# GD32VW553x register map
File version: 1.0
CPU: other RISC-V, little endian, no MPU, FPU
Registers are 32-bit, read-write, reset 0x0 unless marked. A register's access mark holds for its fields unless they carry their own. Offsets are from the block's base; [hi:lo] are bit positions; {n}, {i} and the like mark numbered series.

## SPI — Serial peripheral interface
Base 0x40013000
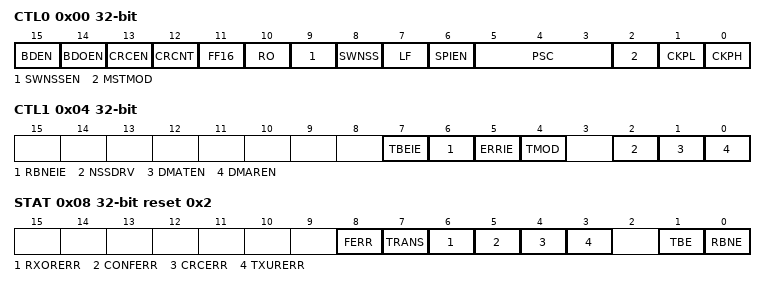
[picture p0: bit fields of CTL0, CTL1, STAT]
0x00 CTL0 — Control register 0
  [15] BDEN — Bidirectional enable
  [14] BDOEN — Bidirectional transmit output enable
  [13] CRCEN — CRC calculation enable
  [12] CRCNT — CRC next transfer
  [11] FF16 — Data frame format
  [10] RO — Receive only mode
  [9] SWNSSEN — NSS software mode enable
  [8] SWNSS — NSS pin selection in NSS software mode
  [7] LF — LSB first mode
  [6] SPIEN — SPI enable
  [5:3] PSC — Master clock prescaler selection
  [2] MSTMOD — Master mode enable
  [1] CKPL — Clock polarity selection
  [0] CKPH — Clock phase selection
0x04 CTL1 — Control register 1
  [7] TBEIE — Transmit buffer empty interrupt enable
  [6] RBNEIE — Receive buffer not empty interrupt enable
  [5] ERRIE — Errors interrupt enable
  [4] TMOD — SPI TI mode enable
  [2] NSSDRV — Drive NSS output
  [1] DMATEN — Transmit buffer DMA enable
  [0] DMAREN — Receive buffer DMA enable
0x08 STAT access per field reset 0x2 — Status register
  [8] FERR rw — Format error
  [7] TRANS ro — Transmitting ongoing bit
  [6] RXORERR ro — Reception overrun error bit
  [5] CONFERR ro — SPI Configuration error
  [4] CRCERR rw — SPI CRC error bit
  [3] TXURERR ro — Transmission underrun error bit
  [1] TBE ro — Transmit buffer empty
  [0] RBNE ro — Receive buffer not empty
0x0C DATA
  [15:0] SPI_DATA — Data transfer register
0x10 CRCPOLY reset 0x7 — CRC polynomial register
  [15:0] CRCPOLY — CRC polynomial value
0x14 RCRC ro — RX CRC register
  [15:0] RCRC — RX CRC value
0x18 TCRC ro — TX CRC register
  [15:0] TCRC — TX CRC value

## SYSCFG — System configuration registers
Base 0x40013800
0x00 CFG0 ro — Configuration register 0
  [1:0] BOOT_MODE — Boot mode (Refer to Boot configuration for details)
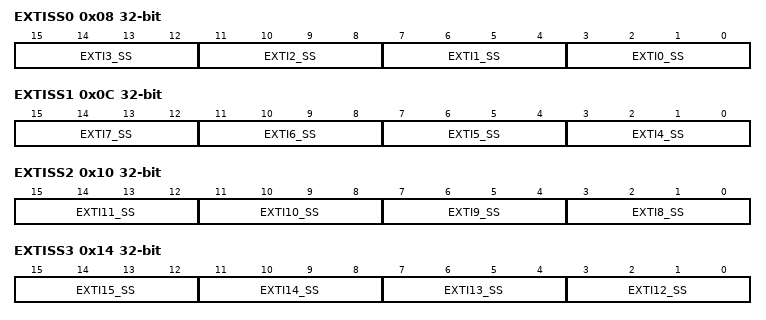
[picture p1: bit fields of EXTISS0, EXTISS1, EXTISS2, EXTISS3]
0x08 EXTISS0 — EXTI sources selection register 0
  [4n+3:4n] EXTI{n}_SS (n=0..3) — EXTI {n} sources selection
0x0C EXTISS1 — EXTI sources selection register 1
  [4n-13:4n-16] EXTI{n}_SS (n=4..7) — EXTI {n} sources selection
0x10 EXTISS2 — EXTI sources selection register 2
  [4n-29:4n-32] EXTI{n}_SS (n=8..11) — EXTI {n} sources selection
0x14 EXTISS3 — EXTI sources selection register 3
  [4n-45:4n-48] EXTI{n}_SS (n=12..15) — EXTI {n} sources selection
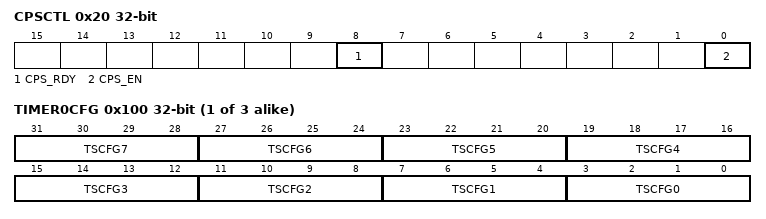
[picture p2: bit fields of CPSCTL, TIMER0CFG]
0x20 CPSCTL access per field — I/O compensation control register
  [8] CPS_RDY ro — Compensation cell ready flag
  [0] CPS_EN rw — Compensation cell power-down
0x54 CFG1 ro — SYSCFG configuration register 1
  [2] LVD_LOCK — LVD lockup bit
0x68 SCFG reset 0x1 — SYSCFG shared SRAM configuration register
  [0] SOWNSEL — Shared SRAM ownership select
{0x100+4i} TIMER{i}CFG (i=0..2) — TIMER trigger selection regist {i}
  [4n+3:4n] TSCFG{n} (n=0..7) — Trigger selection {n}

## TIMER15 — General-purpose-timers
Base 0x40018000
Same registers: TIMER16 0x40018400
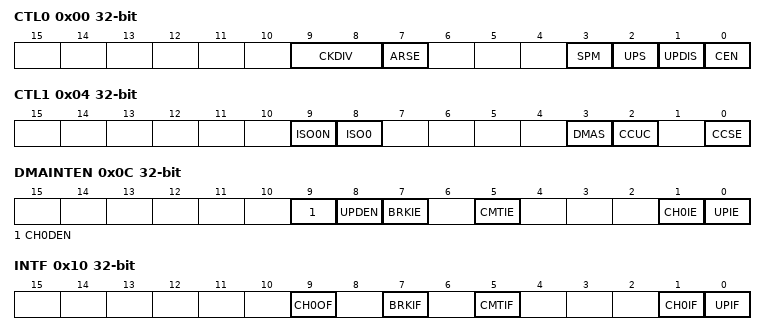
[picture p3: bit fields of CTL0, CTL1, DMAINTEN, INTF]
0x00 CTL0 — control register 0
  [9:8] CKDIV — Clock division
  [7] ARSE — Auto-reload preload enable
  [3] SPM — One-pulse mode
  [2] UPS — Update request source
  [1] UPDIS — Update disable
  [0] CEN — Counter enable
0x04 CTL1 — control register 1
  [9] ISO0N — Output Idle state 0
  [8] ISO0 — Output Idle state 0
  [3] DMAS — Capture/compare DMA selection
  [2] CCUC — Capture/compare control update selection
  [0] CCSE — Capture/compare preloaded control
0x0C DMAINTEN — DMA/Interrupt enable register
  [9] CH0DEN — Capture/Compare 0 DMA request enable
  [8] UPDEN — Update DMA request enable
  [7] BRKIE — Break interrupt enable
  [5] CMTIE — COM interrupt enable
  [1] CH0IE — Capture/Compare 0 interrupt enable
  [0] UPIE — Update interrupt enable
0x10 INTF — interrupt flag register
  [9] CH0OF — Capture/Compare 0 overcapture flag
  [7] BRKIF — Break interrupt flag
  [5] CMTIF — COM interrupt flag
  [1] CH0IF — Capture/compare 0 interrupt flag
  [0] UPIF — Update interrupt flag
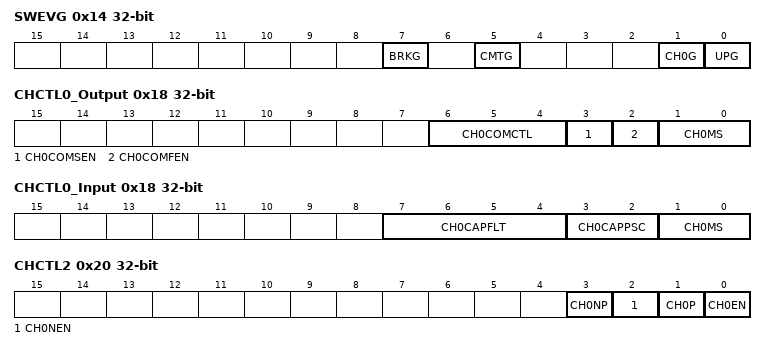
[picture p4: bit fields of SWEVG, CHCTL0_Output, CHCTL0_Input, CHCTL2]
0x14 SWEVG wo — event generation register
  [7] BRKG — Break generation
  [5] CMTG — Capture/Compare control update generation
  [1] CH0G — Capture/compare 0 generation
  [0] UPG — Update generation
0x18 CHCTL0_Output — capture/compare mode register (output mode)
  [6:4] CH0COMCTL — Output Compare 0 mode
  [3] CH0COMSEN — Output Compare 0 preload enable
  [2] CH0COMFEN — Output Compare 0 fast enable
  [1:0] CH0MS — Capture/Compare 0 selection
0x18 CHCTL0_Input (alternate view of CHCTL0_Output) — capture/compare mode register 0 (input mode)
  [7:4] CH0CAPFLT — Input capture 0 filter
  [3:2] CH0CAPPSC — Input capture 0 prescaler
  [1:0] CH0MS — Capture/Compare 0 selection
0x20 CHCTL2 — capture/compare enable register
  [3] CH0NP — Capture/Compare 0 output Polarity
  [2] CH0NEN — Capture/Compare 0 complementary output enable
  [1] CH0P — Capture/Compare 0 output Polarity
  [0] CH0EN — Capture/Compare 0 output enable
0x24 CNT — counter
  [15:0] CNT — counter value
0x28 PSC — prescaler
  [15:0] PSC — Prescaler value
0x2C CAR — auto-reload register
  [15:0] CARL — Auto-reload value
0x30 CREP — repetition counter register
  [7:0] CREP — Repetition counter value
0x34 CH0CV — capture/compare register 0
  [15:0] CH0VAL — Capture/Compare 0 value
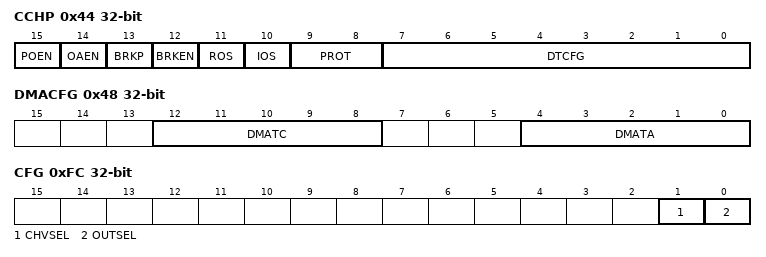
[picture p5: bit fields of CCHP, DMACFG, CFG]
0x44 CCHP — break and dead-time register
  [15] POEN — Main output enable
  [14] OAEN — Automatic output enable
  [13] BRKP — Break polarity
  [12] BRKEN — Break enable
  [11] ROS — Off-state selection for Run mode
  [10] IOS — Off-state selection for Idle mode
  [9:8] PROT — complementary register protect control
  [7:0] DTCFG — Dead-time generator setup
0x48 DMACFG — DMA configuration register
  [12:8] DMATC — DMA transfer count
  [4:0] DMATA — DMA transfer access start address
0x4C DMATB — DMA transfer buffer register
  [15:0] DMATB — DMA register for burst accesses
0xFC CFG — configuration register
  [1] CHVSEL — Write CHxVAL register selection
  [0] OUTSEL — The output value selection
